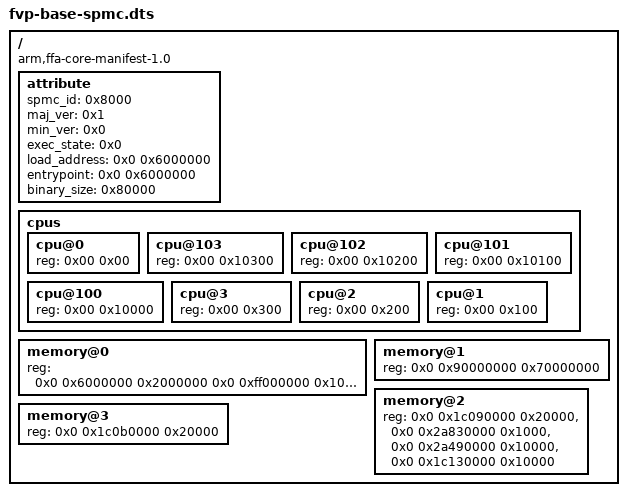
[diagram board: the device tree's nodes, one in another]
/*
 * Copyright 2020 The Hafnium Authors.
 *
 * Use of this source code is governed by a BSD-style
 * license that can be found in the LICENSE file or at
 * https://opensource.org/licenses/BSD-3-Clause.
 */

/dts-v1/;

/ {
	compatible = "arm,ffa-core-manifest-1.0";
	#address-cells = <2>;
	#size-cells = <1>;

	attribute {
		spmc_id = <0x8000>;
		maj_ver = <0x1>;
		min_ver = <0x0>;
		exec_state = <0x0>;
		load_address = <0x0 0x6000000>;
		entrypoint = <0x0 0x6000000>;
		binary_size = <0x80000>;
	};

	cpus {
		#address-cells = <0x02>;
		#size-cells = <0x00>;

		cpu@0 {
			device_type = "cpu";
			reg = <0x00 0x00>;
		};

		cpu@103 {
			device_type = "cpu";
			reg = <0x00 0x10300>;
		};

		cpu@102 {
			device_type = "cpu";
			reg = <0x00 0x10200>;
		};

		cpu@101 {
			device_type = "cpu";
			reg = <0x00 0x10100>;
		};

		cpu@100 {
			device_type = "cpu";
			reg = <0x00 0x10000>;
		};

		cpu@3 {
			device_type = "cpu";
			reg = <0x00 0x300>;
		};

		cpu@2 {
			device_type = "cpu";
			reg = <0x00 0x200>;
		};

		cpu@1 {
			device_type = "cpu";
			reg = <0x00 0x100>;
		};
	};

	memory@0 {
		device_type = "memory";
		reg = <0x0 0x6000000 0x2000000 0x0 0xff000000 0x1000000>;
	};

	memory@1 {
		device_type = "ns-memory";
		/*
		 * This node should include only any memory that is NS and expected to
		 * be handled by the SPMC or any other SP.
		 *
		 * Currently the address range below includes also the address space of
		 * the PVM to simplify the handling of allocation of regions for memory
		 * sharing tests and rxtx buffers. This, however shouldn't be done in
		 * the real world.
		 */
		reg = <0x0 0x90000000 0x70000000>;
	};

	memory@2 {
		device_type = "device-memory";
		reg = <0x0 0x1c090000 0x20000>, /* UART0-1 */
		      <0x0 0x2a830000 0x1000>,  /* AP_REFCLK CNTBase1*/
		      <0x0 0x2a490000 0x10000>, /* Trusted Watchdog */
		      <0x0 0x1c130000 0x10000>; /* Dummy for boot_fail tests. */
	};

	memory@3 {
		device_type = "ns-device-memory";
		reg = <0x0 0x1c0b0000 0x20000>; /* UART2-3 */
	};
};
